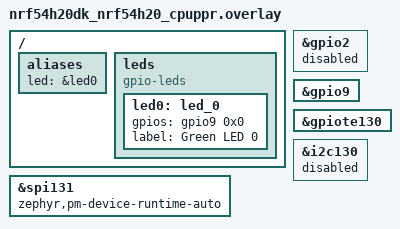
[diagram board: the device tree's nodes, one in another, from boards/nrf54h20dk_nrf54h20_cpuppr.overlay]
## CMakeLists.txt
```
#
# Copyright (c) 2024 Nordic Semiconductor ASA
#
# SPDX-License-Identifier: LicenseRef-Nordic-5-Clause
#

cmake_minimum_required(VERSION 3.20.0)

find_package(Zephyr REQUIRED HINTS $ENV{ZEPHYR_BASE})

if(NOT SYSBUILD)
  message(FATAL_ERROR
    " This is a multi-image application that should be built using sysbuild.\n"
    " Add --sysbuild argument to west build command to prepare all the images."
  )
endif()

project(idle_spim)

target_sources(app PRIVATE src/main.c)
```

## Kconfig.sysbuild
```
#
# Copyright (c) 2025 Nordic Semiconductor ASA
#
# SPDX-License-Identifier: LicenseRef-Nordic-5-Clause
#

source "share/sysbuild/Kconfig"

choice NETCORE
	default NETCORE_REMOTE_SLEEP_FOREVER

config NETCORE_REMOTE_SLEEP_FOREVER
	bool "Remote sleep forever image"

endchoice

config NETCORE_IMAGE_NAME
	default "remote_sleep_forever" if NETCORE_REMOTE_SLEEP_FOREVER

config NETCORE_IMAGE_PATH
	default "${ZEPHYR_NRF_MODULE_DIR}/tests/benchmarks/power_consumption/common/remote_sleep_forever" if NETCORE_REMOTE_SLEEP_FOREVER
```

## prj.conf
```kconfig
CONFIG_SPI=y
CONFIG_GPIO=y

CONFIG_BOOT_BANNER=n
CONFIG_NCS_BOOT_BANNER=n
CONFIG_ASSERT=y

# Enable for debugging purposes only
CONFIG_PRINTK=n
CONFIG_LOG=n
CONFIG_CONSOLE=n
CONFIG_UART_CONSOLE=n
CONFIG_SERIAL=n
```

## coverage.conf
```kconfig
CONFIG_SPI=y
CONFIG_GPIO=y

CONFIG_PM=y
CONFIG_PM_DEVICE=y
CONFIG_PM_DEVICE_RUNTIME=y
CONFIG_POWEROFF=y

CONFIG_BOOT_BANNER=n
CONFIG_NCS_BOOT_BANNER=n
CONFIG_ASSERT=n
CONFIG_CLOCK_CONTROL=n

CONFIG_PRINTK=y
CONFIG_LOG=n
CONFIG_CONSOLE=y
CONFIG_UART_CONSOLE=y

CONFIG_LOG_BUFFER_SIZE=16384
```

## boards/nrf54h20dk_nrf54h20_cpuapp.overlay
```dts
/*
 * Copyright (c) 2024 Nordic Semiconductor ASA
 *
 * SPDX-License-Identifier: LicenseRef-Nordic-5-Clause
 */

/ {
	aliases {
		led = &led0;
		/delete-property/ led1;
	};
};

/delete-node/ &led1;

&spi131 {
};

&exmif {
	status = "disabled";
};
```

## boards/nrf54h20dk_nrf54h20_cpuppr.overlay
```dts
/*
 * Copyright (c) 2025 Nordic Semiconductor ASA
 *
 * SPDX-License-Identifier: LicenseRef-Nordic-5-Clause
 */

/ {
	aliases {
		led = &led0;
	};

	leds {
		compatible = "gpio-leds";

		led0: led_0 {
			gpios = <&gpio9 0x0 0x0>;
			label = "Green LED 0";
		};
	};
};

&gpio2 {
	status = "disabled";
};

&gpio9 {
	status = "okay";
};

&gpiote130 {
	status = "okay";
};

&i2c130 {
	status = "disabled";
};

&spi131 {
	zephyr,pm-device-runtime-auto;
};
```

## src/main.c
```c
/*
 * Copyright (c) 2024 Nordic Semiconductor ASA
 *
 * SPDX-License-Identifier: LicenseRef-Nordic-5-Clause
 */

#include <zephyr/kernel.h>
#include <zephyr/logging/log.h>
#include <zephyr/drivers/spi.h>
#include <zephyr/drivers/gpio.h>

static const struct gpio_dt_spec led = GPIO_DT_SPEC_GET(DT_ALIAS(led), gpios);

LOG_MODULE_REGISTER(idle_spim);

#define SPI_MODE		 SPI_WORD_SET(8) | SPI_TRANSFER_MSB
#define SPI_READ_MASK		 0x80
#define CHIP_ID_REGISTER_ADDRESS 0x00
#define SPI_READ_COUNT		 50

static struct spi_dt_spec spim_spec =
	SPI_DT_SPEC_GET(DT_NODELABEL(bmi270), SPI_OP_MODE_CONTROLLER | SPI_MODE);

void spi_read_register(uint8_t register_address, uint8_t *register_value)
{
	int rc;
	uint8_t tx_buffer[3] = {register_address | SPI_READ_MASK, 0xFF, 0xFF};
	uint8_t rx_buffer[3];

	struct spi_buf tx_spi_buf = {.buf = tx_buffer, .len = sizeof(tx_buffer)};
	struct spi_buf_set tx_spi_buf_set = {.buffers = &tx_spi_buf, .count = 1};
	struct spi_buf rx_spi_bufs = {.buf = rx_buffer, .len = sizeof(rx_buffer)};
	struct spi_buf_set rx_spi_buf_set = {.buffers = &rx_spi_bufs, .count = 1};

	rc = spi_transceive_dt(&spim_spec, &tx_spi_buf_set, &rx_spi_buf_set);
	__ASSERT(rc == 0, "Error: spi_transceive_dt, err: %d\n", rc);
	*register_value = rx_buffer[2];

	__ASSERT(rx_buffer[2] == 0x24, "Invalid CHIP ID %x (0x24)", rx_buffer[2]);

	printk("'spi_transceive_dt', rx_data: %x %x %x\n", rx_buffer[0], rx_buffer[1],
	       rx_buffer[2]);
}

int main(void)
{
	bool status;
	uint8_t response;
	int test_repetitions = 3;

	status = gpio_is_ready_dt(&led);
	__ASSERT(status, "Error: GPIO Device not ready");

	status = gpio_pin_configure_dt(&led, GPIO_OUTPUT_ACTIVE);
	__ASSERT(status == 0, "Could not configure led GPIO");

	status = spi_is_ready_dt(&spim_spec);
	__ASSERT(status, "Error: SPI device is not ready");

#if defined(CONFIG_COVERAGE)
	printk("Coverage analysis enabled\n");
	while (test_repetitions--)
#else
	while (test_repetitions)
#endif
	{
		for (int read_index = 0; read_index < SPI_READ_COUNT; read_index++) {
			spi_read_register(CHIP_ID_REGISTER_ADDRESS, &response);
			printk("Chip ID: 0x%x\n", response);
		}
		gpio_pin_set_dt(&led, 0);
		k_msleep(1000);
		gpio_pin_set_dt(&led, 1);
	}

#if defined(CONFIG_COVERAGE)
	printk("Coverage analysis start\n");
#endif
	return 0;
}
```
